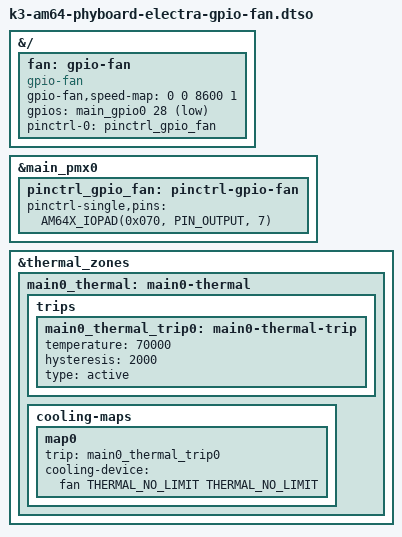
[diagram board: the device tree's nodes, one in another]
// SPDX-License-Identifier: GPL-2.0
/*
 * Copyright (C) 2023 PHYTEC America LLC
 * Author: Nathan Morrisson <nmorrisson@phytec.com>
 */

/dts-v1/;
/plugin/;

#include <dt-bindings/gpio/gpio.h>
#include "k3-pinctrl.h"
#include <dt-bindings/thermal/thermal.h>

&{/} {
	fan: gpio-fan {
		compatible = "gpio-fan";
		gpio-fan,speed-map = <0 0 8600 1>;
		gpios = <&main_gpio0 28 GPIO_ACTIVE_LOW>;
		#cooling-cells = <2>;
		pinctrl-names = "default";
		pinctrl-0 = <&pinctrl_gpio_fan>;
		status = "okay";
	};
};

&main_pmx0 {
	pinctrl_gpio_fan: pinctrl-gpio-fan {
		pinctrl-single,pins = <
			AM64X_IOPAD(0x070, PIN_OUTPUT, 7) /* (V18) GPMC0_AD13.GPIO0_28 */
		>;
	};
};

&thermal_zones {
	main0_thermal: main0-thermal {
		trips {
			main0_thermal_trip0: main0-thermal-trip {
				temperature = <70000>;  /* millicelsius */
				hysteresis = <2000>;    /* millicelsius */
				type = "active";
			};
		};

		cooling-maps {
			map0 {
				trip = <&main0_thermal_trip0>;
				cooling-device = <&fan THERMAL_NO_LIMIT THERMAL_NO_LIMIT>;
			};
		};
	};
};
